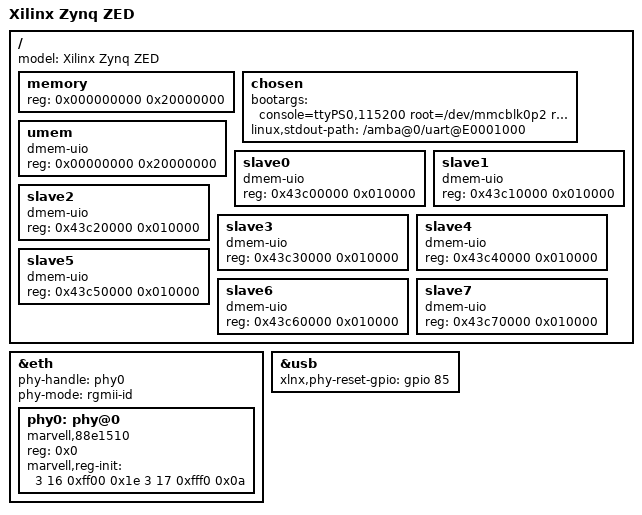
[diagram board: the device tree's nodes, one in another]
/include/ "zynq.dtsi"

/ {
	model = "Xilinx Zynq ZED";
	memory {
		device_type = "memory";
		reg = <0x000000000 0x20000000>;
	};

	chosen {
//		bootargs = "console=ttyPS0,115200 root=/dev/ram rw initrd=0x1100000,33M ip=:::::eth0:dhcp earlyprintk";
// Static allocation (CMA size = 128 MB)
//		bootargs = "console=ttyPS0,115200 root=/dev/mmcblk0p2 rw earlyprintk rootfstype=ext4 rootwait devtmpfs.mount=1 coherent_pool=128M";
// Dynamic allocation by udmabuf driver
		bootargs = "console=ttyPS0,115200 root=/dev/mmcblk0p2 rw earlyprintk rootfstype=ext4 rootwait";
		linux,stdout-path = "/amba@0/uart@E0001000";
	};
  umem {
    compatible = "dmem-uio";
    reg = < 0x00000000 0x20000000 >; // (address, size)
  };
  slave0 {
    compatible = "dmem-uio";
    reg = < 0x43c00000 0x010000 >; // (address, size)
  };
  slave1 {
    compatible = "dmem-uio";
    reg = < 0x43c10000 0x010000 >; // (address, size)
  };
  slave2 {
    compatible = "dmem-uio";
    reg = < 0x43c20000 0x010000 >; // (address, size)
  };
  slave3 {
    compatible = "dmem-uio";
    reg = < 0x43c30000 0x010000 >; // (address, size)
  };
  slave4 {
    compatible = "dmem-uio";
    reg = < 0x43c40000 0x010000 >; // (address, size)
  };
  slave5 {
    compatible = "dmem-uio";
    reg = < 0x43c50000 0x010000 >; // (address, size)
  };
  slave6 {
    compatible = "dmem-uio";
    reg = < 0x43c60000 0x010000 >; // (address, size)
  };
  slave7 {
    compatible = "dmem-uio";
    reg = < 0x43c70000 0x010000 >; // (address, size)
  };
};

&eth {
	phy-handle = <&phy0>;
	phy-mode = "rgmii-id";

	phy0: phy@0 {
		compatible = "marvell,88e1510";
		device_type = "ethernet-phy";
		reg = <0x0>;
		marvell,reg-init=<3 16 0xff00 0x1e 3 17 0xfff0 0x0a>;
	};
};

&usb {
	xlnx,phy-reset-gpio = <&gpio 85 0>;
};
